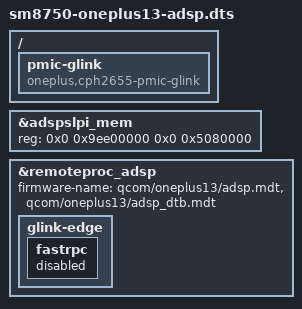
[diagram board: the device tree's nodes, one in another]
// SPDX-License-Identifier: BSD-3-Clause
/* CPH2655 .501 firmware only; load PAS manually after installing verified
 * firmware in RAM. Modem, CDSP and FastRPC stay disabled in this experiment. */
#include "sm8750-oneplus13-controls.dts"

/ {
    pmic-glink {
        compatible = "oneplus,cph2655-pmic-glink", "qcom,sm8750-pmic-glink", "qcom,sm8550-pmic-glink", "qcom,pmic-glink";
    };
};

&adspslpi_mem {
    /* The captured firmware requires 80.5 MiB, larger than upstream's map. */
    reg = <0x0 0x9ee00000 0x0 0x5080000>;
};

&remoteproc_adsp {
    firmware-name = "qcom/oneplus13/adsp.mdt", "qcom/oneplus13/adsp_dtb.mdt";
    status = "okay";
    glink-edge {
        fastrpc { status = "disabled"; };
    };
};
